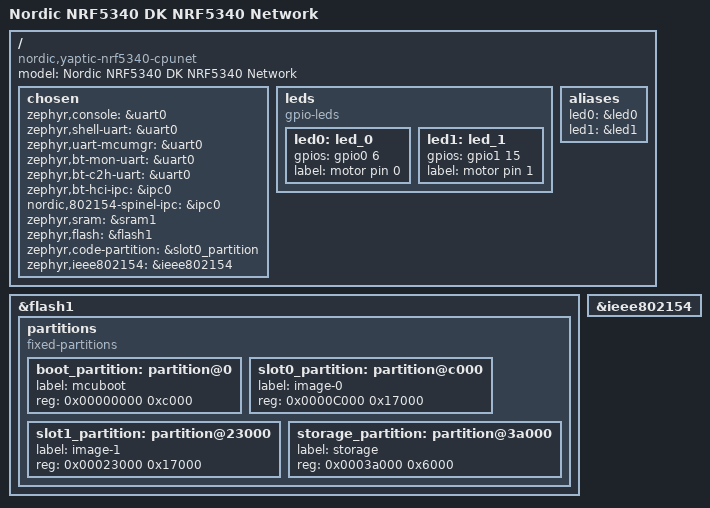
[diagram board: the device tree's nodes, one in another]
/*
 * Copyright (c) 2020 Nordic Semiconductor ASA
 *
 * SPDX-License-Identifier: Apache-2.0
 */

/dts-v1/;
#include <nordic/nrf5340_cpunet_qkaa.dtsi>
#include "yaptic_nrf5340_cpunet-pinctrl.dtsi"
#include <zephyr/dt-bindings/input/input-event-codes.h>

/ {
	model = "Nordic NRF5340 DK NRF5340 Network";
	compatible = "nordic,yaptic-nrf5340-cpunet";

	chosen {
		zephyr,console = &uart0;
		zephyr,shell-uart = &uart0;
		zephyr,uart-mcumgr = &uart0;
		zephyr,bt-mon-uart = &uart0;
		zephyr,bt-c2h-uart = &uart0;
		zephyr,bt-hci-ipc = &ipc0;
		nordic,802154-spinel-ipc = &ipc0;
		zephyr,sram = &sram1;
		zephyr,flash = &flash1;
		zephyr,code-partition = &slot0_partition;
		zephyr,ieee802154 = &ieee802154;
	};

	leds {
		compatible = "gpio-leds";
		led0: led_0 {
			gpios = <&gpio0 6 GPIO_ACTIVE_HIGH>;
			label = "motor pin 0";	
		};
		led1: led_1 {
			gpios = <&gpio1 15 GPIO_ACTIVE_HIGH>;
			label = "motor pin 1";	
		};
	};

	aliases {
		led0 = &led0;
		led1 = &led1;
		};
};
&flash1 {

	partitions {
		compatible = "fixed-partitions";
		#address-cells = <1>;
		#size-cells = <1>;

		boot_partition: partition@0 {
			label = "mcuboot";
			reg = <0x00000000 0xc000>;
		};
		slot0_partition: partition@c000 {
			label = "image-0";
			reg = <0x0000C000 0x17000>;
		};
		slot1_partition: partition@23000 {
			label = "image-1";
			reg = <0x00023000 0x17000>;
		};
		storage_partition: partition@3a000 {
			label = "storage";
			reg = <0x0003a000 0x6000>;
		};
	};
};

&ieee802154 {
	status = "okay";
};

/* Include shared RAM configuration file */
#include "yaptic_shared_sram_planning_conf.dtsi"
